AUTOSAR XML (schema 4-3-0)
package /MICROSAR/BswM_swc
  data type mapping set BswMMappingSet: mode-request-type-map{implementation-data-type=Dcm_DiagnosticSessionControlType, mode-group=DcmDiagnosticSessionControl}  # Contains Mapping for ModeDeclarations Groups which are provided by BswM.
package /MICROSAR/BswM_swc/ComponentTypes
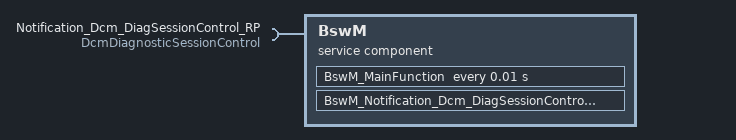
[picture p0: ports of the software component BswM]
  service sw component type BswM: category=SERVICE_COMPONENT
    require port Notification_Dcm_DiagSessionControl_RP: mode-switch-receiver-com-spec=enhanced-mode-api=true, required-interface=DcmDiagnosticSessionControl
    behavior BswMInternalBehavior: data-type-mapping=BswMMappingSet, handle-termination-and-restart=NO-SUPPORT, port-api-option{enable-take-address=true, indirect-api=false, port=Notification_Dcm_DiagSessionControl_RP}
      timing event Timer_BswM_MainFunction: start-on-event=BswM_MainFunction, period=0.01
      swc mode switch event MST_BswM_Notification_Dcm_DiagSessionControl_RP_Notification_Dcm_DiagSessionControl_RP_ON_ENTRY_DEFAULT_SESSION: start-on-event=BswM_Notification_Dcm_DiagSessionControl_RP, activation=ON-ENTRY, mode=Notification_Dcm_DiagSessionControl_RP.DcmDiagnosticSessionControl.DEFAULT_SESSION
      swc mode switch event MST_BswM_Notification_Dcm_DiagSessionControl_RP_Notification_Dcm_DiagSessionControl_RP_ON_ENTRY_PROGRAMMING_SESSION: start-on-event=BswM_Notification_Dcm_DiagSessionControl_RP, activation=ON-ENTRY, mode=Notification_Dcm_DiagSessionControl_RP.DcmDiagnosticSessionControl.PROGRAMMING_SESSION
      swc mode switch event MST_BswM_Notification_Dcm_DiagSessionControl_RP_Notification_Dcm_DiagSessionControl_RP_ON_ENTRY_EXTENDED_SESSION: start-on-event=BswM_Notification_Dcm_DiagSessionControl_RP, activation=ON-ENTRY, mode=Notification_Dcm_DiagSessionControl_RP.DcmDiagnosticSessionControl.EXTENDED_SESSION
      runnable BswM_MainFunction
      runnable BswM_Notification_Dcm_DiagSessionControl_RP: can-be-invoked-concurrently=true, mode-access-point=Notification_Dcm_DiagSessionControl_RP.DcmDiagnosticSessionControl
  swc implementation BswMImplementation: programming-language=C, behavior=BswMInternalBehavior
